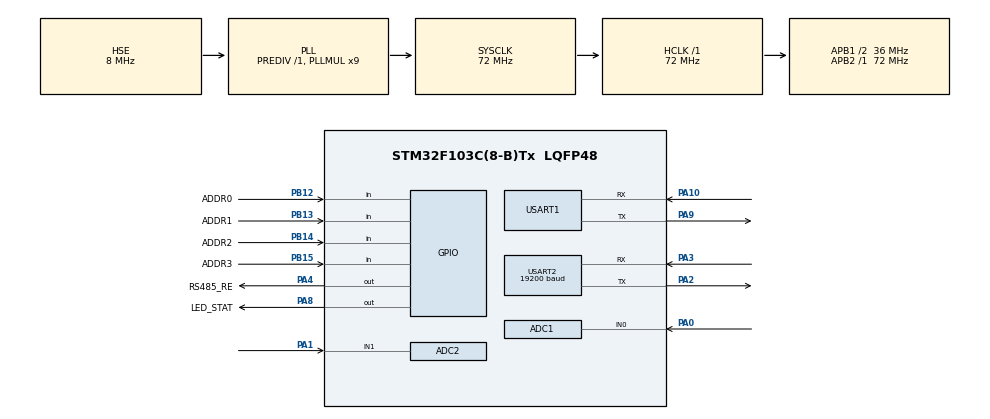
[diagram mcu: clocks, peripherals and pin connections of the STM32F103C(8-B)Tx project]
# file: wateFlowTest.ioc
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ADC1.Channel-3\#ChannelRegularConversion=ADC_CHANNEL_0
ADC1.ContinuousConvMode=DISABLE
ADC1.DiscontinuousConvMode=DISABLE
ADC1.EnableRegularConversion=ENABLE
ADC1.ExternalTrigConv=ADC_EXTERNALTRIGCONV_T4_CC4
ADC1.NbrOfConversion=1
ADC1.NbrOfConversionFlag=1
ADC1.Rank-3\#ChannelRegularConversion=1
ADC1.SamplingTime-3\#ChannelRegularConversion=ADC_SAMPLETIME_1CYCLE_5
ADC1.master=1
ADC2.Channel-0\#ChannelRegularConversion=ADC_CHANNEL_1
ADC2.ContinuousConvMode=ENABLE
ADC2.ExternalTrigConv=ADC_SOFTWARE_START
ADC2.NbrOfConversionFlag=1
ADC2.Rank-0\#ChannelRegularConversion=1
ADC2.SamplingTime-0\#ChannelRegularConversion=ADC_SAMPLETIME_13CYCLES_5
Dma.ADC1.1.Direction=DMA_PERIPH_TO_MEMORY
Dma.ADC1.1.Instance=DMA1_Channel1
Dma.ADC1.1.MemDataAlignment=DMA_MDATAALIGN_HALFWORD
Dma.ADC1.1.MemInc=DMA_MINC_ENABLE
Dma.ADC1.1.Mode=DMA_CIRCULAR
Dma.ADC1.1.PeriphDataAlignment=DMA_PDATAALIGN_HALFWORD
Dma.ADC1.1.PeriphInc=DMA_PINC_DISABLE
Dma.ADC1.1.Priority=DMA_PRIORITY_LOW
Dma.Request0=USART1_RX
Dma.Request1=ADC1
Dma.Request2=USART2_RX
Dma.USART1_RX.0.Direction=DMA_PERIPH_TO_MEMORY
Dma.USART1_RX.0.Instance=DMA1_Channel5
Dma.USART1_RX.0.MemDataAlignment=DMA_MDATAALIGN_BYTE
Dma.USART1_RX.0.MemInc=DMA_MINC_ENABLE
Dma.USART1_RX.0.Mode=DMA_CIRCULAR
Dma.USART1_RX.0.PeriphDataAlignment=DMA_PDATAALIGN_BYTE
Dma.USART1_RX.0.PeriphInc=DMA_PINC_DISABLE
Dma.USART1_RX.0.Priority=DMA_PRIORITY_HIGH
Dma.USART2_RX.2.Direction=DMA_PERIPH_TO_MEMORY
Dma.USART2_RX.2.Instance=DMA1_Channel6
Dma.USART2_RX.2.MemDataAlignment=DMA_MDATAALIGN_BYTE
Dma.USART2_RX.2.MemInc=DMA_MINC_ENABLE
Dma.USART2_RX.2.Mode=DMA_CIRCULAR
Dma.USART2_RX.2.PeriphDataAlignment=DMA_PDATAALIGN_BYTE
Dma.USART2_RX.2.PeriphInc=DMA_PINC_DISABLE
Dma.USART2_RX.2.Priority=DMA_PRIORITY_HIGH
Mcu.Family=STM32F1
Mcu.Name=STM32F103C(8-B)Tx
Mcu.Package=LQFP48
NVIC.ADC1_2_IRQn=true\:0\:0\:false\:false\:true\:true\:true\:true
NVIC.DMA1_Channel1_IRQn=true\:0\:0\:false\:false\:true\:false\:true\:true
NVIC.DMA1_Channel5_IRQn=true\:0\:0\:false\:false\:true\:false\:true\:true
NVIC.DMA1_Channel6_IRQn=true\:0\:0\:false\:false\:true\:false\:true\:true
NVIC.PriorityGroup=NVIC_PRIORITYGROUP_4
NVIC.TIM3_IRQn=true\:0\:0\:false\:false\:true\:true\:true\:true
NVIC.USART1_IRQn=true\:0\:0\:false\:false\:true\:true\:true\:true
NVIC.USART2_IRQn=true\:0\:0\:false\:false\:true\:true\:true\:true
PA0-WKUP.Signal=ADCx_IN0
PA1.Signal=ADCx_IN1
PA10.Mode=Asynchronous
PA10.Signal=USART1_RX
PA13.Mode=Serial_Wire
PA13.Signal=SYS_JTMS-SWDIO
PA14.Mode=Serial_Wire
PA14.Signal=SYS_JTCK-SWCLK
PA2.Mode=Asynchronous
PA2.Signal=USART2_TX
PA3.Mode=Asynchronous
PA3.Signal=USART2_RX
PA4.GPIO_Label=RS485_RE
PA4.GPIO_Speed=GPIO_SPEED_FREQ_MEDIUM
PA4.PinState=GPIO_PIN_SET
PA4.Signal=GPIO_Output
PA8.GPIO_Label=LED_STAT
PA8.Signal=GPIO_Output
PA9.Mode=Asynchronous
PA9.Signal=USART1_TX
PB12.GPIO_Label=ADDR0
PB12.Signal=GPIO_Input
PB13.GPIO_Label=ADDR1
PB13.Signal=GPIO_Input
PB14.GPIO_Label=ADDR2
PB14.Signal=GPIO_Input
PB15.GPIO_Label=ADDR3
PB15.Signal=GPIO_Input
PD0-OSC_IN.Mode=HSE-External-Oscillator
PD0-OSC_IN.Signal=RCC_OSC_IN
PD1-OSC_OUT.Mode=HSE-External-Oscillator
PD1-OSC_OUT.Signal=RCC_OSC_OUT
ProjectManager.HeapSize=0x400
ProjectManager.StackSize=0x1000
ProjectManager.TargetToolchain=MDK-ARM V5.32
RCC.ADCPresc=RCC_ADCPCLK2_DIV6
RCC.AHBFreq_Value=72000000
RCC.APB1CLKDivider=RCC_HCLK_DIV2
RCC.APB1Freq_Value=36000000
RCC.APB1TimFreq_Value=72000000
RCC.APB2Freq_Value=72000000
RCC.APB2TimFreq_Value=72000000
RCC.HCLKFreq_Value=72000000
RCC.PLLMUL=RCC_PLL_MUL9
RCC.PLLSourceVirtual=RCC_PLLSOURCE_HSE
RCC.SYSCLKFreq_VALUE=72000000
RCC.SYSCLKSource=RCC_SYSCLKSOURCE_PLLCLK
RCC.USBFreq_Value=72000000
SH.ADCx_IN0.0=ADC1_IN0,IN0
SH.ADCx_IN1.0=ADC2_IN1,IN1
TIM3.AutoReloadPreload=TIM_AUTORELOAD_PRELOAD_ENABLE
TIM3.Period=50000-1
TIM3.Prescaler=72-1
TIM4.AutoReloadPreload=TIM_AUTORELOAD_PRELOAD_ENABLE
TIM4.Channel-PWM\ Generation4\ No\ Output=TIM_CHANNEL_4
TIM4.Period=10-1
TIM4.Prescaler=72-1
TIM4.Pulse-PWM\ Generation4\ No\ Output=5
USART1.VirtualMode=VM_ASYNC
USART2.BaudRate=19200
USART2.VirtualMode=VM_ASYNC
VP_TIM3_VS_ClockSourceINT.Mode=Internal
VP_TIM4_VS_ClockSourceINT.Mode=Internal
VP_TIM4_VS_no_output4.Mode=PWM Generation4 No Output
board=custom

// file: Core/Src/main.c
/* USER CODE BEGIN Header */
/**
  ******************************************************************************
  * @file           : main.c
  * @brief          : Main program body
  ******************************************************************************
  * @attention
  *
  * Copyright (c) 2023 STMicroelectronics.
  * All rights reserved.
  *
  * This software is licensed under terms that can be found in the LICENSE file
  * in the root directory of this software component.
  * If no LICENSE file comes with this software, it is provided AS-IS.
  *
  ******************************************************************************
  */
/* USER CODE END Header */
#include "main.h"
#include "adc.h"
#include "dma.h"
#include "tim.h"
#include "usart.h"
#include "gpio.h"

/* USER CODE BEGIN Includes */
#include "waterFlow.h"
/* USER CODE END Includes */

void SystemClock_Config(void);

int main(void)
{

  /* MCU Configuration--------------------------------------------------------*/

  /* Reset of all peripherals, Initializes the Flash interface and the Systick. */
  HAL_Init();

  /* Configure the system clock */
  SystemClock_Config();

  /* Initialize all configured peripherals */
  MX_GPIO_Init();
  MX_DMA_Init();
  MX_USART1_UART_Init();
  MX_ADC1_Init();
  MX_USART2_UART_Init();
  MX_TIM3_Init();
  MX_TIM4_Init();
  MX_ADC2_Init();
  /* USER CODE BEGIN 2 */
  initWaterFlowComponet();
  /* USER CODE END 2 */

  /* Infinite loop */
  /* USER CODE BEGIN WHILE */
  while (1)
  {
    LoopWaterFlowComponet();
		//HAL_IWDG_Refresh(&hiwdg);
		// HAL_GPIO_WritePin(LED_STAT_GPIO_Port,LED_STAT_Pin,GPIO_PIN_SET);
		// HAL_Delay(100);
    // HAL_GPIO_WritePin(LED_STAT_GPIO_Port,LED_STAT_Pin,GPIO_PIN_RESET);
    // HAL_Delay(100);
    /* USER CODE END WHILE */

  }
}

void SystemClock_Config(void)
{
  RCC_OscInitTypeDef RCC_OscInitStruct = {0};
  RCC_ClkInitTypeDef RCC_ClkInitStruct = {0};
  RCC_PeriphCLKInitTypeDef PeriphClkInit = {0};

  /** Initializes the RCC Oscillators according to the specified parameters
  * in the RCC_OscInitTypeDef structure.
  */
  RCC_OscInitStruct.OscillatorType = RCC_OSCILLATORTYPE_HSE;
  RCC_OscInitStruct.HSEState = RCC_HSE_ON;
  RCC_OscInitStruct.HSEPredivValue = RCC_HSE_PREDIV_DIV1;
  RCC_OscInitStruct.HSIState = RCC_HSI_ON;
  RCC_OscInitStruct.PLL.PLLState = RCC_PLL_ON;
  RCC_OscInitStruct.PLL.PLLSource = RCC_PLLSOURCE_HSE;
  RCC_OscInitStruct.PLL.PLLMUL = RCC_PLL_MUL9;
  if (HAL_RCC_OscConfig(&RCC_OscInitStruct) != HAL_OK)
  {
    Error_Handler();
  }

  /** Initializes the CPU, AHB and APB buses clocks
  */
  RCC_ClkInitStruct.ClockType = RCC_CLOCKTYPE_HCLK|RCC_CLOCKTYPE_SYSCLK
                              |RCC_CLOCKTYPE_PCLK1|RCC_CLOCKTYPE_PCLK2;
  RCC_ClkInitStruct.SYSCLKSource = RCC_SYSCLKSOURCE_PLLCLK;
  RCC_ClkInitStruct.AHBCLKDivider = RCC_SYSCLK_DIV1;
  RCC_ClkInitStruct.APB1CLKDivider = RCC_HCLK_DIV2;
  RCC_ClkInitStruct.APB2CLKDivider = RCC_HCLK_DIV1;

  if (HAL_RCC_ClockConfig(&RCC_ClkInitStruct, FLASH_LATENCY_2) != HAL_OK)
  {
    Error_Handler();
  }
  PeriphClkInit.PeriphClockSelection = RCC_PERIPHCLK_ADC;
  PeriphClkInit.AdcClockSelection = RCC_ADCPCLK2_DIV6;
  if (HAL_RCCEx_PeriphCLKConfig(&PeriphClkInit) != HAL_OK)
  {
    Error_Handler();
  }
}

/* USER CODE BEGIN 4 */
void HAL_TIM_PeriodElapsedCallback(TIM_HandleTypeDef *htim)
{
  if(htim == &htim3)
  {
    hal_tim_timer3_callback();
  }
}
/* USER CODE END 4 */

void Error_Handler(void)
{
  __disable_irq();
  while (1)
  {
  }
}
